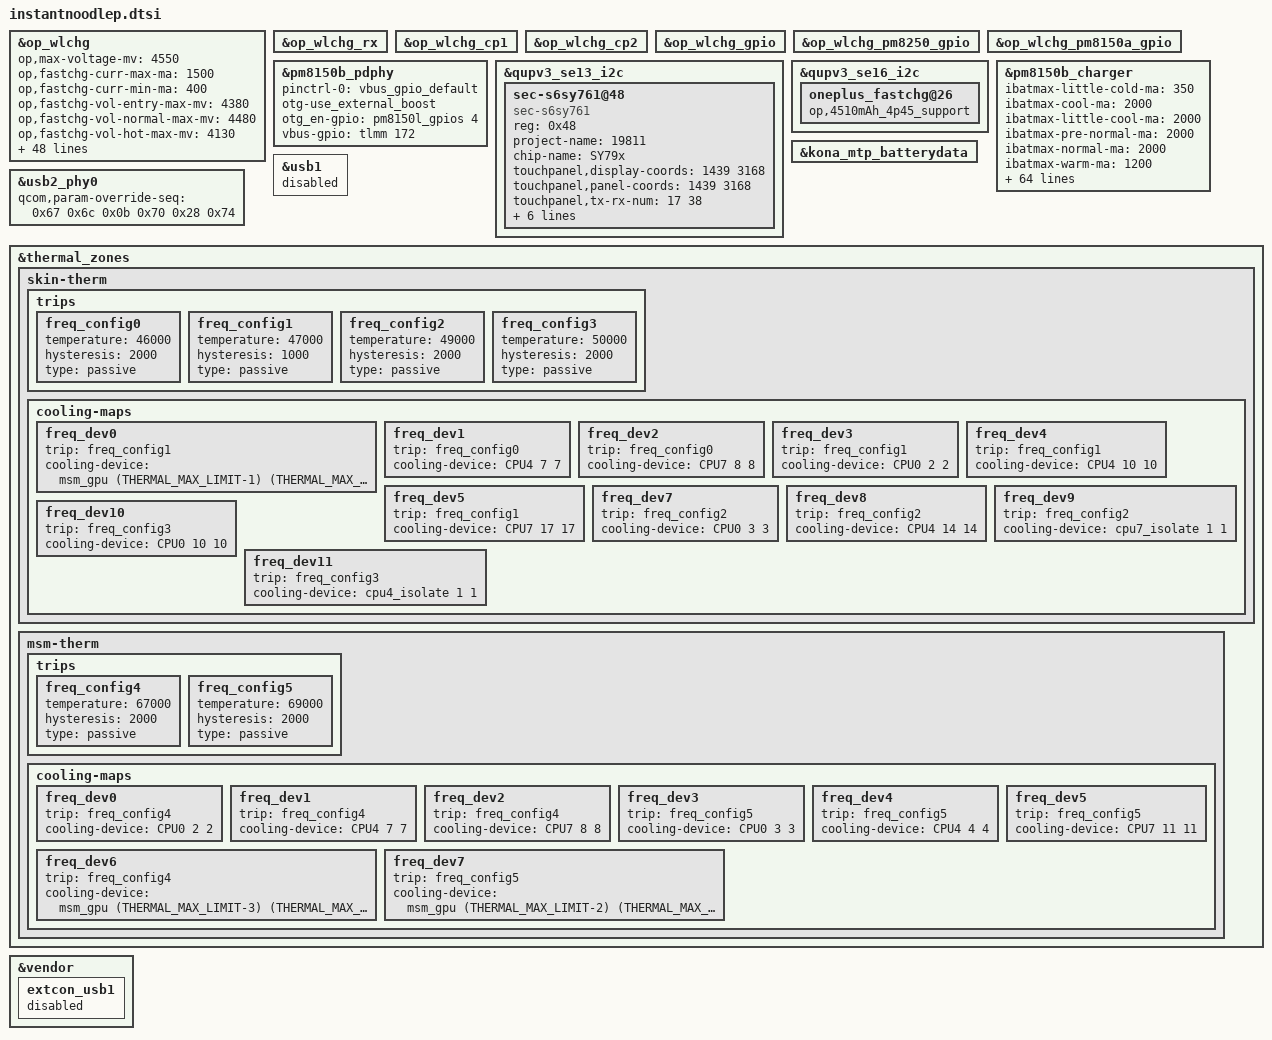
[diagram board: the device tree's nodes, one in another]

&op_wlchg {
	status = "okay";
	op,max-voltage-mv = <4550>;
	op,fastchg-curr-max-ma = <1500>;
	op,fastchg-curr-min-ma = <400>;
	op,fastchg-vol-entry-max-mv = <4380>;
	op,fastchg-vol-normal-max-mv = <4480>;
	op,fastchg-vol-hot-max-mv = <4130>;
	op,fastchg-vol-min-mv = <3300>;
	op,fastchg-temp-max = <430>;
	op,fastchg-temp-min = <120>;
	op,fastchg-soc-max = <85>;
	op,fastchg-soc-min = <1>;
	op,fastchg-soc-mid = <75>;
	op,fastchg-discharge-curr-max = <2000>;
	/*
	 * | temp_min | temp_max | target_curr_ua | vol_max_mv |need wait |
	 *
	 * temp_min: Switch to the previous level when the temperature is lower
	 *           than this value. If it is 0, do not switch.
	 * temp_max: Switch to the next level when the temperature is greater
	 *           than this value
	 * target_curr_ua: Target current in this temperature range.
	 * vol_max_mv: Maximum battery voltage.
	 * need wait: 1:Need wait for a while after switching to the next level.
	 *            0:No need to wait after switching to the next level.
	 */
	op,fastchg-ffc_step = <0   405  1500000 4420 1
			       380 420  1000000 4450 1
			       390 420  850000  4480 1
			       400 420  625000  4480 0>;
	/* ibatmax setting for different temp regions */
	op,epp-ibatmax-ma = <0 1000 2500 2500 2500 2500 1500 0>;
	op,bpp-ibatmax-ma = <0 1000 1500 1500 1500 1500 1500 0>;
	op,bpp-sdp-ibatmax-ma = <0 1000 1000 1000 1000 1000 1000 0>;
	op,epp-iclmax-ma = <0 300 1100 1100 1100 1100 650 0>;
	op,bpp-iclmax-ma = <0 500 1000 1000 1000 1000 1000 0>;
	op,bpp-sdp-iclmax-ma = <0 500 500 500 500 500 500 0>;
	op,fastchg-ibatmax-ma = <4000 6000>;
	/* temp region settings */
	cold-bat-decidegc = <20>;
	little-cold-bat-decidegc = <0>;
	cool-bat-decidegc = <50>;
	little-cool-bat-decidegc = <120>;
	pre-normal-bat-decidegc = <160>;
	warm-bat-decidegc = <440>;
	hot-bat-decidegc = <500>;

	cool-vbat-thr-mv = <4180>;
	cool-epp-ibat-ma = <1500>;
	cool-epp-icl-ma = <650>;
	/* deviation check */
	op,rx-freq-threshold = <129>;

	/*wireless charge skin-therm*/
	fastchg-skin-temp-max = <420>;
	fastchg-skin-temp-min = <400>;
	epp-skin-temp-max = <390>;
	epp-skin-temp-min = <370>;
	op,epp-curr-step = <1100 550>;

	/* fod parameter*/
	op,fastchg-fod-enable;
	op,fastchg-match-q-new = /bits/ 8 <0x56>;
	op,fastchg-match-q = /bits/ 8 <0x44>;
	op,fastchg-fod-parm-new = /bits/ 8 <0xac 0x32 0xac 0x28 0xa0 0xba
					0x9a 0xd3 0x9a 0xce 0x9f 0xf6>;
	op,fastchg-fod-parm = /bits/ 8 <0xac 0x32 0xac 0x28 0xa0 0x1e
					0x9a 0x37 0x9a 0x32 0x9f 0xc4>;
	op,fastchg-fod-parm-startup = /bits/ 8 <0xac 0x7f 0xac 0x28 0xa0 0x1e
						0x9a 0x37 0x9a 0x32 0x9f 0xc4>;

	/* vbatdet setting for different temp regions */
	vbatdet-mv = <0 3675 4235 4370 4370 4370 4030 0>;
};

&op_wlchg_rx {
	status = "okay";
};

&op_wlchg_cp1 {
	status = "okay";
};

&op_wlchg_cp2 {
	status = "okay";
};

&op_wlchg_gpio {
	status = "okay";
};

&op_wlchg_pm8250_gpio {
	status = "okay";
};

&op_wlchg_pm8150a_gpio {
	status = "okay";
};

&pm8150b_pdphy {
	pinctrl-names = "default";
	pinctrl-0 = <&vbus_gpio_default>;
	otg-use_external_boost;
	otg_en-gpio = <&pm8150l_gpios 4 0x00>;
	vbus-gpio = <&tlmm 172 0x00>;
};

&qupv3_se13_i2c {
	status = "ok";
	sec-s6sy761@48 {
		compatible = "sec-s6sy761";
		reg = <0x48>;
		project-name = "19811";
		chip-name = "SY79x";
		touchpanel,display-coords = <1439 3168>;
		touchpanel,panel-coords = <1439 3168>;
		touchpanel,tx-rx-num = <17 38>;
		wireless_charge_support = <1>;
		audio_noise_support = <1>;
		project_info = <1>;
		panel = <&dsi_samsung_oneplus_dsc_cmd
		&dsi_samsung_ana6706_dsc_cmd &dsi_samsung_ana6705_dsc_cmd>;
	};
};

/* @bsp, Battery & Charging config STRAT */
&qupv3_se16_i2c {
	oneplus_fastchg@26{
		op,4510mAh_4p45_support;
	};
};

&pm8150b_charger {
	/* ibatmax setting for different temp regions */
	ibatmax-little-cold-ma = <350>;
	ibatmax-cool-ma = <2000>;
	ibatmax-little-cool-ma = <2000>;
	ibatmax-pre-normal-ma = <2000>;
	ibatmax-normal-ma = <2000>;
	ibatmax-warm-ma = <1200>;
	ibatmax-little-cool-thr-ma = <1900>;
	ibatmax-cool-thr-ma = <1200>;
	/* vbatmax setting for different temp regions */
	vbatmax-little-cold-mv = <3975>;
	vbatmax-cool-mv = <4435>;
	vbatmax-little-cool-mv = <4435>;
	vbatmax-pre-normal-mv = <4435>;
	vbatmax-normal-mv = <4435>;
	vbatmax-warm-mv = <4130>;
	little-cool-vbat-thr-mv = <4180>;
	cool-vbat-thr-mv = <4180>;
	/* vbatdet setting for different temp regions */
	vbatdet-little-cold-mv = <3675>;
	vbatdet-cool-mv = <4235>;
	vbatdet-little-cool-mv = <4335>;
	vbatdet-pre-normal-mv = <4335>;
	vbatdet-normal-mv = <4335>;
	vbatdet-warm-mv = <4030>;
	/* temp region settings */
	cold-bat-decidegc = <20>;
	little-cold-bat-decidegc = <0>;
	cool-bat-decidegc = <50>;
	little-cool-bat-decidegc = <120>;
	pre-normal-bat-decidegc = <160>;
	warm-bat-decidegc = <450>;
	hot-bat-decidegc = <500>;
	qcom,otg-cl-ua = <1500000>;
	op,sw-iterm-ma = <310>;
	op,sw-check-full-enable;
	/* temp region settings */
	cold-bat-decidegc = <20>;
	little-cold-bat-decidegc = <0>;
	cool-bat-decidegc = <50>;
	little-cool-bat-decidegc = <120>;
	pre-normal-bat-decidegc = <160>;
	warm-bat-decidegc = <450>;
	hot-bat-decidegc = <500>;
	qcom,otg-cl-ua = <1500000>;
	op,sw-iterm-ma = <235>;
	op,sw-check-full-enable;

	/*ffc temp region*/
	ffc-pre-normal-decidegc = <120>;
	ffc-normal-decidegc = <350>;
	ffc-warm-decidegc = <400>;
	ffc-normal-fcc-ma = <1000>;
	ffc-warm-fcc-ma = <1050>;
	ffc-normal-cutoff-ma = <850>;
	ffc-warm-cutoff-ma = <900>;
	ffc-full-vbat-mv = <4480>;

	/* skin thermal temp adjust the dash current */
	op,skin-thermal-high-threshold = <41>;
	op,skin-thermal-pre-high-threshold = <39>;
	op,skin-thermal-medium-threshold = <38>;
	op,skin-thermal-normal-threshold = <36>;
	op,skin-thermal-lcdoff-high-threshold = <41>;
	op,skin-thermal-lcdoff-pre-high-threshold = <39>;
	op,skin-thermal-lcdoff-medium-threshold = <38>;
	op,skin-thermal-lcdoff-normal-threshold = <36>;
	op,enable-dash-current-dynamic-adjust;

	/* skin thermal temp adjust the normal charger path current */
	op,nor-skin-thermal-high-threshold = <39>;
	op,nor-skin-thermal-pre-high-threshold = <37>;
	op,nor-skin-thermal-warm-threshold = <36>;
	op,nor-skin-thermal-pre-warm-threshold = <35>;
	op,nor-skin-thermal-medium-threshold = <34>;
	op,nor-skin-thermal-normal-threshold = <33>;
	op,nor-skin-thermal-lcdoff-high-threshold = <39>;
	op,nor-skin-thermal-lcdoff-pre-high-threshold = <37>;
	op,nor-skin-thermal-lcdoff-warm-threshold = <36>;
	op,nor-skin-thermal-lcdoff-pre-warm-threshold = <35>;
	op,nor-skin-thermal-lcdoff-medium-threshold = <34>;
	op,nor-skin-thermal-lcdoff-normal-threshold = <33>;
	op,nor-call-on-current-ma = <1800>;
	op,nor-skin-thermal-high-current-ma = <2000>;
	op,nor-skin-thermal-warm-current-ma = <3000>;
	op,nor-skin-thermal-medium-current-ma = <3000>;
	op,enable-nor-current-dynamic-adjust;
};

&kona_mtp_batterydata {
	#include "OP-fg-batterydata-4510mah.dtsi"
};

&usb2_phy0 {
	qcom,param-override-seq =
		<0x67 0x6c/*Disconnection voltage +21.56%*/
		0x0b 0x70/*Pre-emphasis:4x DC voltage level:+17.80%*/
		0x28 0x74>;
};

&usb1 {
	status = "disabled";
};

&thermal_zones {
	skin-therm {
		trips {
			freq_config0: freq_config0 {
				temperature = <46000>;
				hysteresis = <2000>;
				type = "passive";
			};
			freq_config1: freq_config1 {
				temperature = <47000>;
				hysteresis = <1000>;
				type = "passive";
			};
			freq_config2: freq_config2 {
				temperature = <49000>;
				hysteresis = <2000>;
				type = "passive";
			};
			freq_config3: freq_config3 {
				temperature = <50000>;
				hysteresis = <2000>;
				type = "passive";
			};
		};
		cooling-maps {
			freq_dev0 {
				trip = <&freq_config1>;
				cooling-device =
					<&msm_gpu (THERMAL_MAX_LIMIT-1) (THERMAL_MAX_LIMIT-1)>;/*345*/
			};
			freq_dev1 {
				trip = <&freq_config0>;
				cooling-device =
					<&CPU4 7 7>;/*1766*/
			};
			freq_dev2 {
				trip = <&freq_config0>;
				cooling-device =
					<&CPU7 8 8>;/*2073*/
			};
			freq_dev3 {
				trip = <&freq_config1>;
				cooling-device =
					<&CPU0 2 2>;/*1612*/
			};
			freq_dev4 {
				trip = <&freq_config1>;
				cooling-device =
					<&CPU4 10 10>;/*1478*/
			};
			freq_dev5 {
				trip = <&freq_config1>;
				cooling-device =
					<&CPU7 17 17>;/*1075*/
			};
			freq_dev7 {
				trip = <&freq_config2>;
				cooling-device =
					<&CPU0 3 3>;/*1516*/
			};
			freq_dev8 {
				trip = <&freq_config2>;
				cooling-device =
					<&CPU4 14 14>;/*1056*/
			};
			freq_dev9 {
				trip = <&freq_config2>;
				cooling-device =
					<&cpu7_isolate 1 1>;
			};
			freq_dev10 {
				trip = <&freq_config3>;
				cooling-device =
					<&CPU0 10 10>;/*883*/
			};
			freq_dev11 {
				trip = <&freq_config3>;
				cooling-device =
					<&cpu4_isolate 1 1>;
			};
		};
	};

	msm-therm {
		trips {
			freq_config4: freq_config4 {
				temperature = <67000>;
				hysteresis = <2000>;
				type = "passive";
			};
			freq_config5: freq_config5 {
				temperature = <69000>;
				hysteresis = <2000>;
				type = "passive";
			};
		};
		cooling-maps {
			freq_dev0 {
				trip = <&freq_config4>;
				cooling-device =
					<&CPU0 2 2>;/*1612 17*/
			};
			freq_dev1 {
				trip = <&freq_config4>;
				cooling-device =
					<&CPU4 7 7>;/*1766 18*/
			};
			freq_dev2 {
				trip = <&freq_config4>;
				cooling-device =
					<&CPU7 8 8>;/*2073 20*/
			};
			freq_dev3 {
				trip = <&freq_config5>;
				cooling-device =
					<&CPU0 3 3>;/*1382*/
			};
			freq_dev4 {
				trip = <&freq_config5>;
				cooling-device =
					<&CPU4 4 4>;/*1748*/
			};
			freq_dev5 {
				trip = <&freq_config5>;
				cooling-device =
					<&CPU7 11 11>;/*1747*/
			};
			freq_dev6 {
				trip = <&freq_config4>;
				cooling-device =
					<&msm_gpu (THERMAL_MAX_LIMIT-3)
						(THERMAL_MAX_LIMIT-3)>;/*441*/
			};
			freq_dev7 {
				trip = <&freq_config5>;
				cooling-device =
					<&msm_gpu (THERMAL_MAX_LIMIT-2)
						(THERMAL_MAX_LIMIT-2)>;/*400*/
			};
		};
	};

};

&vendor {
	extcon_usb1 {
		status = "disabled";
	};
};
